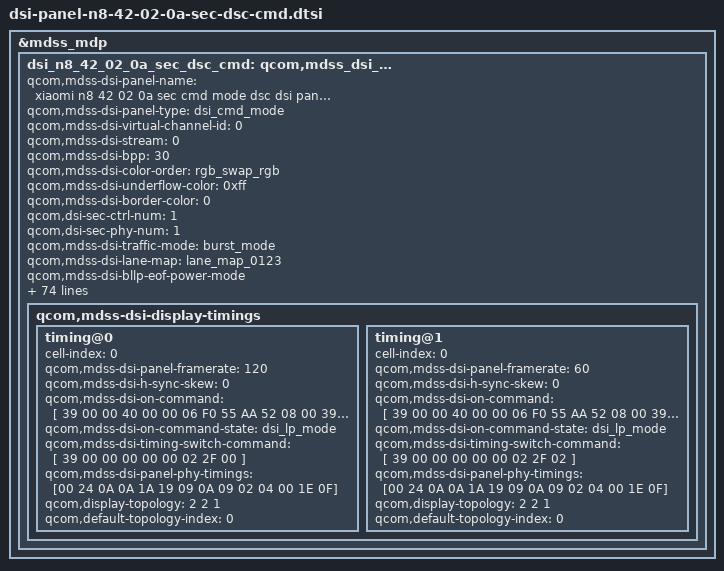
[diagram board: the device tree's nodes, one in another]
&mdss_mdp {
	dsi_n8_42_02_0a_sec_dsc_cmd: qcom,mdss_dsi_n8_42_02_0a_sec_dsc_cmd {
		qcom,mdss-dsi-panel-name = "xiaomi n8 42 02 0a sec cmd mode dsc dsi panel";
		qcom,mdss-dsi-panel-type = "dsi_cmd_mode";
		qcom,mdss-dsi-virtual-channel-id = <0>;
		qcom,mdss-dsi-stream = <0>;
		qcom,mdss-dsi-bpp = <30>;
		qcom,mdss-dsi-color-order = "rgb_swap_rgb";
		qcom,mdss-dsi-underflow-color = <0xff>;
		qcom,mdss-dsi-border-color = <0>;
		qcom,dsi-sec-ctrl-num = <1>;
		qcom,dsi-sec-phy-num = <1>;

		qcom,mdss-dsi-traffic-mode = "burst_mode";
		qcom,mdss-dsi-lane-map = "lane_map_0123";
		qcom,mdss-dsi-bllp-eof-power-mode;
		qcom,mdss-dsi-bllp-power-mode;
		qcom,mdss-dsi-lane-0-state;
		qcom,mdss-dsi-lane-1-state;
		//qcom,mdss-dsi-lane-2-state;
		//qcom,mdss-dsi-lane-3-state;
		qcom,mdss-dsi-dma-trigger = "trigger_sw";
		qcom,mdss-dsi-mdp-trigger = "none";
		qcom,mdss-dsi-reset-sequence = <1 1>, <0 1>, <1 10>;
		qcom,mdss-pan-physical-width-dimension = <668>;
		qcom,mdss-pan-physical-height-dimension = <769>;
		qcom,mdss-dsi-te-pin-select = <1>;
		qcom,mdss-dsi-wr-mem-start = <0x2c>;
		qcom,mdss-dsi-wr-mem-continue = <0x3c>;
		qcom,mdss-dsi-te-dcs-command = <1>;
		qcom,mdss-dsi-te-check-enable;
		qcom,mdss-dsi-te-using-te-pin;
		qcom,mdss-dsi-tx-eot-append;
		qcom,mdss-dsi-lp11-init;

		qcom,mdss-dsi-bl-inverted-dbv;
		qcom,bl-update-flag = "delay_until_first_frame";

		qcom,mdss-dsi-panel-hdr-enabled;
		qcom,mdss-dsi-panel-hdr-color-primaries = <14500 15500 32000
			17000 15500 30000 8000 3000>;
		qcom,mdss-dsi-panel-peak-brightness = <4200000>;
		qcom,mdss-dsi-panel-blackness-level = <3230>;

		qcom,mdss-dsi-dma-schedule-line = <1>;
		qcom,mdss-dsi-dma-schedule-window = <50>;

		/* IRQF_ONESHOT | IRQF_TRIGGER_HEIGH */
		mi,esd-err-irq-gpio = <&tlmm 137 0x2004>;
		//qcom,spr-pack-type = "pentile";

		mi,panel-id = <0x00004E38 0x5342020A>;

		mi,ddic-round-corner-enabled;

		mi,flat-need-sync-te;
		mi,flatmode-default-on-enabled;

		mi,flatmode-status-check-enabled;
		mi,mdss-dsi-panel-flatmode-status-command = [
			06 01 00 01 00 00 01 5F
		];
		mi,mdss-dsi-panel-flatmode-status-command-state = "dsi_hs_mode";
		mi,mdss-dsi-panel-flatmode-status-read-length = <1>;
		mi,mdss-dsi-panel-flatmode-on-status-value = <0x00>;

		mi,mdss-dsi-panel-wp-read-command = [06 01 00 01 00 00 01 A3];
		mi,mdss-dsi-panel-wp-read-command-state = "dsi_hs_mode";
		mi,mdss-dsi-panel-wp-read-length = <8>;
		/* esd-check reg_read */
		//qcom,esd-check-enabled;
		//qcom,esd-aod-check-enabled;
		//mi,mdss-dsi-panel-status-check-interval = <1000>;
		//qcom,mdss-dsi-panel-status-check-mode = "reg_read";
		//mi,mdss-dsi-panel-status-offset-command = [39 00 00 00 00 00 03 FF 5A 82
		//					      39 00 00 00 00 00 02 65 01];
		//qcom,mdss-dsi-panel-status-command = [06 01 00 00 00 00 01 F9];
		//mi,mdss-dsi-panel-status-after-command = [39 00 00 00 00 00 03 FF 5A 00];
		//qcom,mdss-dsi-panel-status-command-state = "dsi_lp_mode";
		//mi,mdss-dsi-panel-status-offset-command-state = "dsi_lp_mode";
		//mi,mdss-dsi-panel-status-after-command-state = "dsi_lp_mode";
		//qcom,mdss-dsi-panel-status-value = <0x08>;
		//qcom,mdss-dsi-panel-status-read-length = <1>;

		mi,panel-on-dimming-delay = <120>;
		mi,max-brightness-clone = <16383>;
		mi,normal-max-brightness-clone = <8191>;
		mi,thermal-dimming-flag;

		mi,mdss-dsi-fac-bl-max-level = <11467>;
		mi,mdss-fac-brightness-max-level = <11467>;
		mi,doze-hbm-dbv-level = <1311>;
		mi,doze-lbm-dbv-level = <80>;

		qcom,mdss-dsi-display-timings {
			timing@0 {
				#include "dsi-panel-n8-42-02-0a-sec-dsc-cmd-common.dtsi"
				cell-index = <0>;
				qcom,mdss-dsi-panel-framerate = <120>;
				qcom,mdss-dsi-h-sync-skew = <0>;

				qcom,mdss-dsi-on-command = [
					/* esd config */
 					39 00 00 40 00 00 06 F0 55 AA 52 08 00
 					39 00 00 40 00 00 03 BE 47 45
 					39 00 00 40 00 00 02 6F 05
 					39 00 00 40 00 00 02 BE 28
 					39 00 00 40 00 00 02 6F 19
 					39 00 00 40 00 00 05 BE 10 91 00 AB
 					39 00 00 40 00 00 02 6F 0D
 					39 00 00 00 00 00 02 D8 42
					/* turn on round */
					39 00 00 40 00 00 06 F0 55 AA 52 08 07
					39 00 00 40 00 00 02 6F 03
					39 00 00 40 00 00 05 C0 00 00 00 00
					39 00 00 40 00 00 16 C1 31 0F 08 A1 01 44 F9 64 3F F7 B6 1C 3F F5 5D 5C 00 01 FD 42 A0
					39 00 00 40 00 00 02 6F 15
					39 00 00 40 00 00 11 C1 31 00 4F C7 00 1D 4E 33 F0 CF 88 16 F8 00 00 00
					39 00 00 40 00 00 02 6F 25
					39 00 00 40 00 00 08 C1 00 3A 4E 00 01 0A 00
					39 00 00 40 00 00 16 C2 39 0F 00 E1 08 44 FA 9C 3F F6 3B D4 3F F8 71 D8 00 01 B9 FC 24
					39 00 00 40 00 00 02 6F 15
					39 00 00 40 00 00 11 C2 75 00 1E 4C 00 51 C6 33 F0 8B D2 15 06 00 00 00
					39 00 00 40 00 00 02 6F 25
					39 00 00 40 00 00 08 C2 00 4D 5B 00 50 5A 00
					39 00 00 40 00 00 16 C3 3C 00 03 84 00 C4 03 48 3F FE 7E 20 00 00 00 00 00 00 00 00 00
					39 00 00 40 00 00 02 6F 15
					39 00 00 40 00 00 11 C3 32 00 00 0E 55 2A 61 43 C0 CA 0E 00 00 00 00 00
					39 00 00 40 00 00 02 6F 25
					39 00 00 40 00 00 08 C3 11 27 40 00 50 61 00
					39 00 00 40 00 00 16 C4 30 0F 04 C9 04 41 F6 FA 3F FB 18 EE 3F FB 4F 1A 00 00 F4 91 25
					39 00 00 40 00 00 02 6F 15
					39 00 00 40 00 00 11 C4 18 00 0B 4E 00 0B 50 22 F0 BB BD 12 0F 00 00 00
					39 00 00 40 00 00 02 6F 25
					39 00 00 40 00 00 08 C4 00 4E 6B 00 4F 4F 00
					39 00 00 40 00 00 16 C5 30 0F 00 51 0A F9 FC 46 3F FF B1 9E 3F FD D8 3A 00 00 12 85 D1
					39 00 00 40 00 00 02 6F 15
					39 00 00 40 00 00 11 C5 0B 00 4F B8 00 00 0B 33 F0 F5 97 04 83 00 00 00
					39 00 00 40 00 00 02 6F 25
					39 00 00 40 00 00 08 C5 11 21 3F 00 4F 50 00
					39 00 00 40 00 00 16 C6 38 0F 08 44 00 51 FC C4 3F FE 21 94 3F FF B5 BC 00 00 10 A6 80
					39 00 00 40 00 00 02 6F 15
					39 00 00 40 00 00 11 C6 64 00 00 0B 00 51 B5 33 F0 9C F5 04 4C 00 00 00
					39 00 00 40 00 00 02 6F 25
					39 00 00 40 00 00 08 C6 00 00 0A 00 45 50 00
					39 00 00 40 00 00 16 C7 34 00 00 C4 02 A4 02 D8 3F FF 85 80 00 00 7A 80 00 00 00 00 00
					39 00 00 40 00 00 02 6F 15
					39 00 00 40 00 00 11 C7 0E 00 0F 45 55 61 6F 33 C0 F2 36 00 00 00 00 00
					39 00 00 40 00 00 02 6F 25
					39 00 00 40 00 00 08 C7 00 01 0E 55 62 6C 00
					39 00 00 40 00 00 16 C8 31 00 6E 40 6F 91 00 00 3F 6E 6F 80 3F 6D 91 B0 00 30 0C 32 40
					39 00 00 40 00 00 02 6F 15
					39 00 00 40 00 00 11 C8 31 00 1E C7 12 85 2D 33 F0 58 57 6E E8 00 00 00
					39 00 00 40 00 00 02 6F 25
					39 00 00 40 00 00 08 C8 44 AD B7 00 45 50 00
					39 00 00 40 00 00 16 C9 3D 00 6E 40 6F 91 00 00 3F 6E 6F 80 00 00 00 00 00 00 00 00 00
					39 00 00 40 00 00 02 6F 15
					39 00 00 40 00 00 11 C9 76 00 1E C7 22 2E D6 33 C0 58 A9 00 00 00 00 00
					39 00 00 40 00 00 02 6F 25
					39 00 00 40 00 00 08 C9 44 69 7D 00 01 0A 00
					39 00 00 40 00 00 16 CA 3D 00 6E 40 6F 91 00 00 3F 6E 6F 80 00 00 00 00 00 00 00 00 00
					39 00 00 40 00 00 02 6F 15
					39 00 00 40 00 00 11 CA 76 00 1E C7 01 C7 6F 33 C0 58 A9 00 00 00 00 00
					39 00 00 40 00 00 02 6F 25
					39 00 00 40 00 00 08 CA 44 A9 B6 55 62 6C 00
					39 00 00 40 00 00 0F D1 80 00 00 00 00 01 8D 80 00 00 00 00 01 8D
					39 00 00 40 00 00 02 6F 0E
					39 00 00 40 00 00 0F D1 FF FF ED 96 D0 04 B7 80 00 00 00 00 04 B7
					39 00 00 40 00 00 02 6F 1C
					39 00 00 40 00 00 0F D1 80 00 00 00 00 04 B7 80 00 00 00 00 04 B7
					39 00 00 40 00 00 02 6F 2A
					39 00 00 40 00 00 0C D1 FF FF EE E1 90 04 B7 80 00 00 00
					39 00 00 40 00 00 12 D2 00 01 8D FF CF F3 CD C0 01 8D FF CF F3 CD C0 01 8D
					39 00 00 40 00 00 06 F0 55 AA 52 08 00
					39 00 00 00 00 00 0A 88 01 02 5C 04 E0 00 00 00 00
					/* init code */
					39 00 00 40 00 00 06 F0 55 AA 52 08 02
					39 00 00 40 00 00 02 BE 13
					39 00 00 40 00 00 05 FF AA 55 A5 80
					39 00 00 40 00 00 02 6F 0A
					39 00 00 40 00 00 06 F6 70 70 70 70 70
					39 00 00 40 00 00 05 FF AA 55 A5 80
					39 00 00 40 00 00 02 6F 16
					39 00 00 40 00 00 03 F4 02 74
					39 00 00 40 00 00 05 FF AA 55 A5 80
					39 00 00 40 00 00 02 6F 32
					39 00 00 40 00 00 02 F9 00
					39 00 00 40 00 00 05 FF AA 55 A5 81
					39 00 00 40 00 00 02 6F 0D
					39 00 00 40 00 00 02 FB 80
					39 00 00 40 00 00 05 FF AA 55 A5 81
					39 00 00 40 00 00 02 6F 05
					39 00 00 40 00 00 03 FE 3C 3C
					39 00 00 40 00 00 02 6F 02
					39 00 00 40 00 00 02 F9 04
					39 00 00 40 00 00 02 6F 0C
					39 00 00 40 00 00 02 FD 08
					39 00 00 40 00 00 02 6F 10
					39 00 00 40 00 00 02 FB 04
					39 00 00 40 00 00 05 FF AA 55 A5 80
					39 00 00 40 00 00 02 6F 15
					39 00 00 40 00 00 03 F8 01 8D
					39 00 00 40 00 00 05 FF AA 55 A5 80
					39 00 00 40 00 00 02 6F 42
					39 00 00 40 00 00 02 F4 00
					39 00 00 40 00 00 02 6F 49
					39 00 00 40 00 00 02 F2 10
					39 00 00 40 00 00 02 17 30
					39 00 00 40 00 00 02 16 01
					39 00 00 40 00 00 05 2A 00 00 04 B7
					39 00 00 40 00 00 05 2B 00 00 05 6F
					39 00 00 40 00 00 02 2F 00
					39 00 00 40 00 00 02 5F 00
					39 00 00 40 00 00 02 5A 01
					39 00 00 40 00 00 02 35 00
					39 00 00 40 00 00 03 51 00 00
					39 00 00 40 00 00 02 53 20
					39 00 00 40 00 00 02 90 03
					39 00 00 40 00 00 02 6F 01
					39 00 00 40 00 00 02 90 43
					39 00 00 40 00 00 13 91 AB A8 00 0C C2 00 02 2F 01 30 00 08 08 BB 07 8E 10 F0
					39 00 00 40 00 00 02 6F 06
					39 00 00 40 00 00 02 6D 04
					39 00 00 40 00 00 02 26 00
					/* 109/138.8/Video Track 1.2G */
					39 00 00 40 00 00 06 F0 55 AA 52 08 01
					39 00 00 40 00 00 2A C3 DD 06 20 13 FF 00 06 20 13 FF 00 06 2A 22 06 41 1B 06 2A 22 06 41 1B 06 2A 22 06 41 1B 06 2A 22 06 41 1B 06 2A 22 06 41 1B
					05 00 00 00 78 00 01 11
					05 00 00 00 00 00 01 29
				];
				qcom,mdss-dsi-on-command-state = "dsi_lp_mode";

				qcom,mdss-dsi-timing-switch-command = [
//					/* Auto Dimming OFF */
//					/*Frame skip OFF (Auto Mode)*/
//					/*Frame Skip Mode 1*/
//					/* Frequency Select 120Hz */
					39 00 00 00 00 00 02 2F 00
				];

//				qcom,mdss-dsi-timing-switch-command-state = "dsi_lp_mode";

//				qcom,mdss-dsi-nolp-command = [
//					/*FIX TE OFF*/
//					/* Frequency Select 120Hz */
//				];

//				qcom,mdss-dsi-nolp-command-state = "dsi_lp_mode";
			};
			timing@1 {
				#include "dsi-panel-n8-42-02-0a-sec-dsc-cmd-common.dtsi"
				cell-index = <0>;
				qcom,mdss-dsi-panel-framerate = <60>;
				qcom,mdss-dsi-h-sync-skew = <0>;

				qcom,mdss-dsi-on-command = [
					/* esd config */
 					39 00 00 40 00 00 06 F0 55 AA 52 08 00
 					39 00 00 40 00 00 03 BE 47 45
 					39 00 00 40 00 00 02 6F 05
 					39 00 00 40 00 00 02 BE 28
 					39 00 00 40 00 00 02 6F 19
 					39 00 00 40 00 00 05 BE 10 91 00 AB
 					39 00 00 40 00 00 02 6F 0D
 					39 00 00 00 00 00 02 D8 42
					/* turn on round */
					39 00 00 40 00 00 06 F0 55 AA 52 08 07
					39 00 00 40 00 00 02 6F 03
					39 00 00 40 00 00 05 C0 00 00 00 00
					39 00 00 40 00 00 16 C1 31 0F 08 A1 01 44 F9 64 3F F7 B6 1C 3F F5 5D 5C 00 01 FD 42 A0
					39 00 00 40 00 00 02 6F 15
					39 00 00 40 00 00 11 C1 31 00 4F C7 00 1D 4E 33 F0 CF 88 16 F8 00 00 00
					39 00 00 40 00 00 02 6F 25
					39 00 00 40 00 00 08 C1 00 3A 4E 00 01 0A 00
					39 00 00 40 00 00 16 C2 39 0F 00 E1 08 44 FA 9C 3F F6 3B D4 3F F8 71 D8 00 01 B9 FC 24
					39 00 00 40 00 00 02 6F 15
					39 00 00 40 00 00 11 C2 75 00 1E 4C 00 51 C6 33 F0 8B D2 15 06 00 00 00
					39 00 00 40 00 00 02 6F 25
					39 00 00 40 00 00 08 C2 00 4D 5B 00 50 5A 00
					39 00 00 40 00 00 16 C3 3C 00 03 84 00 C4 03 48 3F FE 7E 20 00 00 00 00 00 00 00 00 00
					39 00 00 40 00 00 02 6F 15
					39 00 00 40 00 00 11 C3 32 00 00 0E 55 2A 61 43 C0 CA 0E 00 00 00 00 00
					39 00 00 40 00 00 02 6F 25
					39 00 00 40 00 00 08 C3 11 27 40 00 50 61 00
					39 00 00 40 00 00 16 C4 30 0F 04 C9 04 41 F6 FA 3F FB 18 EE 3F FB 4F 1A 00 00 F4 91 25
					39 00 00 40 00 00 02 6F 15
					39 00 00 40 00 00 11 C4 18 00 0B 4E 00 0B 50 22 F0 BB BD 12 0F 00 00 00
					39 00 00 40 00 00 02 6F 25
					39 00 00 40 00 00 08 C4 00 4E 6B 00 4F 4F 00
					39 00 00 40 00 00 16 C5 30 0F 00 51 0A F9 FC 46 3F FF B1 9E 3F FD D8 3A 00 00 12 85 D1
					39 00 00 40 00 00 02 6F 15
					39 00 00 40 00 00 11 C5 0B 00 4F B8 00 00 0B 33 F0 F5 97 04 83 00 00 00
					39 00 00 40 00 00 02 6F 25
					39 00 00 40 00 00 08 C5 11 21 3F 00 4F 50 00
					39 00 00 40 00 00 16 C6 38 0F 08 44 00 51 FC C4 3F FE 21 94 3F FF B5 BC 00 00 10 A6 80
					39 00 00 40 00 00 02 6F 15
					39 00 00 40 00 00 11 C6 64 00 00 0B 00 51 B5 33 F0 9C F5 04 4C 00 00 00
					39 00 00 40 00 00 02 6F 25
					39 00 00 40 00 00 08 C6 00 00 0A 00 45 50 00
					39 00 00 40 00 00 16 C7 34 00 00 C4 02 A4 02 D8 3F FF 85 80 00 00 7A 80 00 00 00 00 00
					39 00 00 40 00 00 02 6F 15
					39 00 00 40 00 00 11 C7 0E 00 0F 45 55 61 6F 33 C0 F2 36 00 00 00 00 00
					39 00 00 40 00 00 02 6F 25
					39 00 00 40 00 00 08 C7 00 01 0E 55 62 6C 00
					39 00 00 40 00 00 16 C8 31 00 6E 40 6F 91 00 00 3F 6E 6F 80 3F 6D 91 B0 00 30 0C 32 40
					39 00 00 40 00 00 02 6F 15
					39 00 00 40 00 00 11 C8 31 00 1E C7 12 85 2D 33 F0 58 57 6E E8 00 00 00
					39 00 00 40 00 00 02 6F 25
					39 00 00 40 00 00 08 C8 44 AD B7 00 45 50 00
					39 00 00 40 00 00 16 C9 3D 00 6E 40 6F 91 00 00 3F 6E 6F 80 00 00 00 00 00 00 00 00 00
					39 00 00 40 00 00 02 6F 15
					39 00 00 40 00 00 11 C9 76 00 1E C7 22 2E D6 33 C0 58 A9 00 00 00 00 00
					39 00 00 40 00 00 02 6F 25
					39 00 00 40 00 00 08 C9 44 69 7D 00 01 0A 00
					39 00 00 40 00 00 16 CA 3D 00 6E 40 6F 91 00 00 3F 6E 6F 80 00 00 00 00 00 00 00 00 00
					39 00 00 40 00 00 02 6F 15
					39 00 00 40 00 00 11 CA 76 00 1E C7 01 C7 6F 33 C0 58 A9 00 00 00 00 00
					39 00 00 40 00 00 02 6F 25
					39 00 00 40 00 00 08 CA 44 A9 B6 55 62 6C 00
					39 00 00 40 00 00 0F D1 80 00 00 00 00 01 8D 80 00 00 00 00 01 8D
					39 00 00 40 00 00 02 6F 0E
					39 00 00 40 00 00 0F D1 FF FF ED 96 D0 04 B7 80 00 00 00 00 04 B7
					39 00 00 40 00 00 02 6F 1C
					39 00 00 40 00 00 0F D1 80 00 00 00 00 04 B7 80 00 00 00 00 04 B7
					39 00 00 40 00 00 02 6F 2A
					39 00 00 40 00 00 0C D1 FF FF EE E1 90 04 B7 80 00 00 00
					39 00 00 40 00 00 12 D2 00 01 8D FF CF F3 CD C0 01 8D FF CF F3 CD C0 01 8D
					39 00 00 40 00 00 06 F0 55 AA 52 08 00
					39 00 00 00 00 00 0A 88 01 02 5C 04 E0 00 00 00 00
					/* init code */
					39 00 00 40 00 00 06 F0 55 AA 52 08 02
					39 00 00 40 00 00 02 BE 13
					39 00 00 40 00 00 05 FF AA 55 A5 80
					39 00 00 40 00 00 02 6F 0A
					39 00 00 40 00 00 06 F6 70 70 70 70 70
					39 00 00 40 00 00 05 FF AA 55 A5 80
					39 00 00 40 00 00 02 6F 16
					39 00 00 40 00 00 03 F4 02 74
					39 00 00 40 00 00 05 FF AA 55 A5 80
					39 00 00 40 00 00 02 6F 32
					39 00 00 40 00 00 02 F9 00
					39 00 00 40 00 00 05 FF AA 55 A5 81
					39 00 00 40 00 00 02 6F 0D
					39 00 00 40 00 00 02 FB 80
					39 00 00 40 00 00 05 FF AA 55 A5 81
					39 00 00 40 00 00 02 6F 05
					39 00 00 40 00 00 03 FE 3C 3C
					39 00 00 40 00 00 02 6F 02
					39 00 00 40 00 00 02 F9 04
					39 00 00 40 00 00 02 6F 0C
					39 00 00 40 00 00 02 FD 08
					39 00 00 40 00 00 02 6F 10
					39 00 00 40 00 00 02 FB 04
					39 00 00 40 00 00 05 FF AA 55 A5 80
					39 00 00 40 00 00 02 6F 15
					39 00 00 40 00 00 03 F8 01 8D
					39 00 00 40 00 00 05 FF AA 55 A5 80
					39 00 00 40 00 00 02 6F 42
					39 00 00 40 00 00 02 F4 00
					39 00 00 40 00 00 02 6F 49
					39 00 00 40 00 00 02 F2 10
					39 00 00 40 00 00 02 17 30
					39 00 00 40 00 00 02 16 01
					39 00 00 40 00 00 05 2A 00 00 04 B7
					39 00 00 40 00 00 05 2B 00 00 05 6F
					39 00 00 40 00 00 02 2F 02
					39 00 00 40 00 00 02 5F 00
					39 00 00 40 00 00 02 5A 01
					39 00 00 40 00 00 02 35 00
					39 00 00 40 00 00 03 51 00 00
					39 00 00 40 00 00 02 53 20
					39 00 00 40 00 00 02 90 03
					39 00 00 40 00 00 02 6F 01
					39 00 00 40 00 00 02 90 43
					39 00 00 40 00 00 13 91 AB A8 00 0C C2 00 02 2F 01 30 00 08 08 BB 07 8E 10 F0
					39 00 00 40 00 00 02 6F 06
					39 00 00 40 00 00 02 6D 04
					39 00 00 40 00 00 02 26 00
					/* 109/138.8/Video Track 1.2G */
					39 00 00 40 00 00 06 F0 55 AA 52 08 01
					39 00 00 40 00 00 2A C3 DD 06 20 13 FF 00 06 20 13 FF 00 06 2A 22 06 41 1B 06 2A 22 06 41 1B 06 2A 22 06 41 1B 06 2A 22 06 41 1B 06 2A 22 06 41 1B
					05 00 00 00 78 00 01 11
					05 00 00 00 00 00 01 29
				];
				qcom,mdss-dsi-on-command-state = "dsi_lp_mode";

				qcom,mdss-dsi-timing-switch-command = [
//					/* Auto Dimming OFF */
//					/*Frame skip OFF (Auto Mode)*/
//					/*Frame Skip Mode 1*/
//					/* Frequency Select 120Hz */
					39 00 00 00 00 00 02 2F 02
				];

//				qcom,mdss-dsi-timing-switch-command-state = "dsi_lp_mode";

//				qcom,mdss-dsi-nolp-command = [
//					/*FIX TE OFF*/
//					/* Frequency Select 120Hz */
//				];

//				qcom,mdss-dsi-nolp-command-state = "dsi_lp_mode";
			};
		};
	};
};

&dsi_n8_42_02_0a_sec_dsc_cmd {
	qcom,panel-sec-supply-entries = <&dsi_panel_pwr_supply_sec_N8>;
	qcom,mdss-dsi-sec-bl-pmic-control-type = "bl_ctrl_dcs";
	qcom,mdss-dsi-bl-min-level = <15>;
	qcom,mdss-dsi-bl-max-level = <16383>;
	qcom,bl-dsc-cmd-state = "dsi_lp_mode";
	qcom,mdss-brightness-max-level = <16383>;
	qcom,mdss-brightness-init-level = <307>;
	qcom,platform-sec-reset-gpio = <&tlmm 128 0>;

	mi,panel-build-id-read-needed;
	mi,panel-build-id-read-length = <1>;
	mi,mdss-dsi-panel-build-id-read-command = [06 01 00 01 00 00 01 DA];
	mi,mdss-dsi-panel-build-id-read-command-state = "dsi_hs_mode";

	mi,disable-ic-dimming-flag;
	qcom,mdss-dsi-panel-vsync-delay;
	qcom,ulps-enabled;
	qcom,dsi-select-sec-clocks = "pll_byte_clk1", "pll_dsi_clk1";
	qcom,mdss-dsi-clk-strength = <0xFF>;
	qcom,mdss-dsi-display-timings {
		/* 120Hz */
		timing@0{
				qcom,mdss-dsi-panel-phy-timings = [00 24 0A 0A 1A 19 09 0A 09 02 04 00 1E 0F];
				qcom,display-topology = <2 2 1>;
				qcom,default-topology-index = <0>;
		};
		timing@1{
				qcom,mdss-dsi-panel-phy-timings = [00 24 0A 0A 1A 19 09 0A 09 02 04 00 1E 0F];
				qcom,display-topology = <2 2 1>;
				qcom,default-topology-index = <0>;
		};
	};
};
